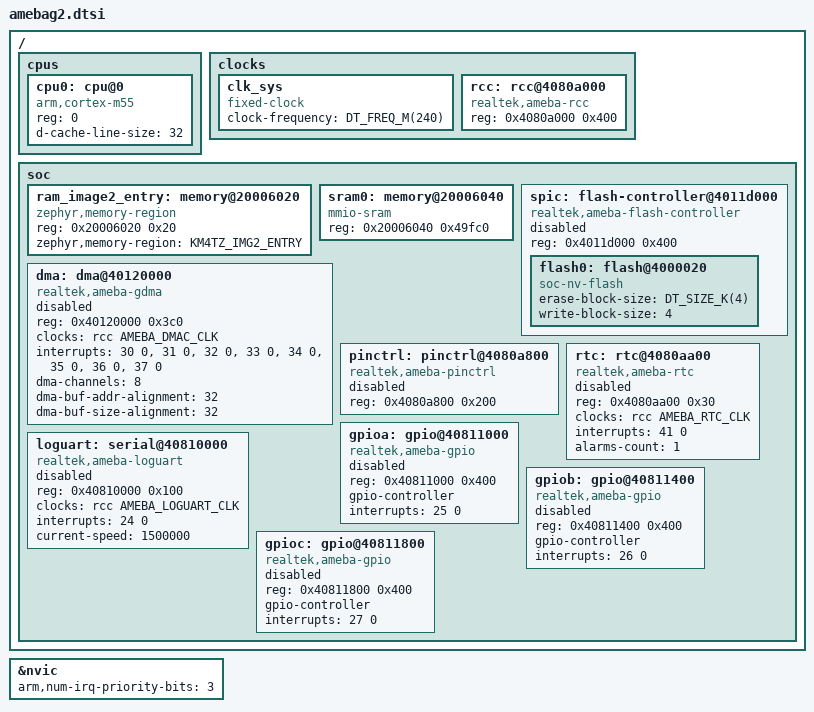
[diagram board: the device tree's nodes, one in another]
/*
 * Copyright (c) 2024 Realtek Semiconductor Corp.
 *
 * SPDX-License-Identifier: Apache-2.0
 */

#include <mem.h>
#include <freq.h>
#include <arm/armv8.1-m.dtsi>
#include <zephyr/dt-bindings/clock/amebag2_clock.h>
#include <zephyr/dt-bindings/dma/ameba_dma.h>
#include <zephyr/dt-bindings/gpio/gpio.h>

/ {
	cpus {
		#address-cells = <1>;
		#size-cells = <0>;

		cpu0: cpu@0 {
			device_type = "cpu";
			compatible = "arm,cortex-m55";
			reg = <0>;
			d-cache-line-size = <32>;
			#address-cells = <1>;
			#size-cells = <1>;
		};
	};

	clocks {
		#address-cells = <1>;
		#size-cells = <1>;

		clk_sys: clk_sys {
			#clock-cells = <0>;
			compatible = "fixed-clock";
			clock-frequency = <DT_FREQ_M(240)>;
		};

		rcc: rcc@4080a000 {
			compatible = "realtek,ameba-rcc";
			#clock-cells = <1>;
			reg = <0x4080a000 0x400>;
		};
	};

	soc {
		ram_image2_entry: memory@20006020 {
			compatible = "zephyr,memory-region";
			reg = <0x20006020 0x20>;
			zephyr,memory-region = "KM4TZ_IMG2_ENTRY";
		};

		sram0: memory@20006040 {
			compatible = "mmio-sram";
			reg = <0x20006040 0x49fc0>;
		};

		spic: flash-controller@4011d000 {
			compatible = "realtek,ameba-flash-controller";
			reg = <0x4011d000 0x400>;

			#address-cells = <1>;
			#size-cells = <1>;
			status = "disabled";

			flash0: flash@4000020 {
				compatible = "soc-nv-flash";
				erase-block-size = <DT_SIZE_K(4)>;
				write-block-size = <4>;
				#address-cells = <1>;
				#size-cells = <1>;
			};
		};

		dma: dma@40120000 {
			compatible = "realtek,ameba-gdma";
			reg = <0x40120000 0x3c0>;
			clocks = <&rcc AMEBA_DMAC_CLK>;
			interrupts = <30 0>, <31 0>, <32 0>, <33 0>, <34 0>, <35 0>, <36 0>, <37 0>;
			interrupt-names = "CH0", "CH1", "CH2", "CH3", "CH4", "CH5", "CH6", "CH7";
			#dma-cells = <3>;
			dma-channels = <8>;
			dma-buf-addr-alignment = <32>;
			dma-buf-size-alignment = <32>;
			status = "disabled";
		};

		pinctrl: pinctrl@4080a800 {
			compatible = "realtek,ameba-pinctrl";
			reg = <0x4080a800 0x200>;
			status = "disabled";
		};

		rtc: rtc@4080aa00 {
			compatible = "realtek,ameba-rtc";
			reg = <0x4080aa00 0x30>;
			clocks = <&rcc AMEBA_RTC_CLK>;
			interrupts = <41 0>;
			alarms-count = <1>;
			status = "disabled";
		};

		loguart: serial@40810000 {
			compatible = "realtek,ameba-loguart";
			reg = <0x40810000 0x100>;
			clocks = <&rcc AMEBA_LOGUART_CLK>;
			interrupts = <24 0>;
			current-speed = <1500000>;
			status = "disabled";
		};

		gpioa: gpio@40811000 {
			compatible = "realtek,ameba-gpio";
			reg = <0x40811000 0x400>;
			gpio-controller;
			#gpio-cells = <2>;
			interrupts = <25 0>;
			status = "disabled";
		};

		gpiob: gpio@40811400 {
			compatible = "realtek,ameba-gpio";
			reg = <0x40811400 0x400>;
			gpio-controller;
			#gpio-cells = <2>;
			interrupts = <26 0>;
			status = "disabled";
		};

		gpioc: gpio@40811800 {
			compatible = "realtek,ameba-gpio";
			reg = <0x40811800 0x400>;
			gpio-controller;
			#gpio-cells = <2>;
			interrupts = <27 0>;
			status = "disabled";
		};
	};
};

&nvic {
	arm,num-irq-priority-bits = <3>;
};
